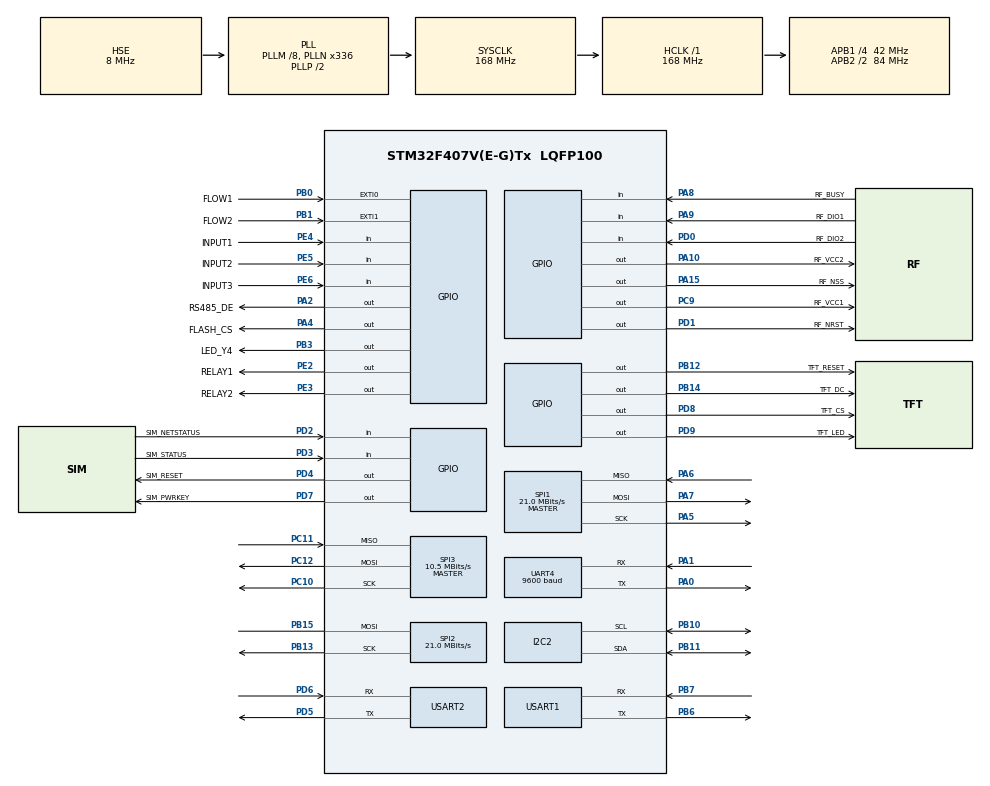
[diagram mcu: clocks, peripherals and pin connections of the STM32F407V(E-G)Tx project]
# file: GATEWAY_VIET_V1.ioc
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Mcu.Family=STM32F4
Mcu.Name=STM32F407V(E-G)Tx
Mcu.Package=LQFP100
NVIC.EXTI0_IRQn=true\:5\:0\:false\:false\:true\:true\:true\:true
NVIC.EXTI1_IRQn=true\:5\:0\:false\:false\:true\:true\:true\:true
NVIC.PriorityGroup=NVIC_PRIORITYGROUP_4
NVIC.UART4_IRQn=true\:5\:0\:false\:false\:true\:true\:true\:true
NVIC.USART1_IRQn=true\:6\:0\:false\:false\:true\:true\:true\:true
NVIC.USART2_IRQn=true\:5\:0\:false\:false\:true\:true\:true\:true
PA0-WKUP.Mode=Asynchronous
PA0-WKUP.Signal=UART4_TX
PA1.Mode=Asynchronous
PA1.Signal=UART4_RX
PA10.GPIO_Label=RF_VCC2
PA10.Signal=GPIO_Output
PA13.Mode=Serial_Wire
PA13.Signal=SYS_JTMS-SWDIO
PA14.Mode=Serial_Wire
PA14.Signal=SYS_JTCK-SWCLK
PA15.GPIO_Label=RF_NSS
PA15.PinState=GPIO_PIN_SET
PA15.Signal=GPIO_Output
PA2.GPIO_Label=RS485_DE
PA2.Signal=GPIO_Output
PA4.GPIO_Label=FLASH_CS
PA4.PinState=GPIO_PIN_SET
PA4.Signal=GPIO_Output
PA5.Mode=Full_Duplex_Master
PA5.Signal=SPI1_SCK
PA6.Mode=Full_Duplex_Master
PA6.Signal=SPI1_MISO
PA7.Mode=Full_Duplex_Master
PA7.Signal=SPI1_MOSI
PA8.GPIO_Label=RF_BUSY
PA8.Signal=GPIO_Input
PA9.GPIO_Label=RF_DIO1
PA9.Signal=GPIO_Input
PB0.GPIO_Label=FLOW1
PB0.GPIO_ModeDefaultEXTI=GPIO_MODE_IT_FALLING
PB0.Signal=GPXTI0
PB1.GPIO_Label=FLOW2
PB1.GPIO_ModeDefaultEXTI=GPIO_MODE_IT_FALLING
PB1.Signal=GPXTI1
PB10.Mode=I2C
PB10.Signal=I2C2_SCL
PB11.Mode=I2C
PB11.Signal=I2C2_SDA
PB12.GPIO_Label=TFT_RESET
PB12.PinState=GPIO_PIN_SET
PB12.Signal=GPIO_Output
PB13.Mode=Simplex_Bidirectional_Master
PB13.Signal=SPI2_SCK
PB14.GPIO_Label=TFT_DC
PB14.Signal=GPIO_Output
PB15.Mode=Simplex_Bidirectional_Master
PB15.Signal=SPI2_MOSI
PB3.GPIO_Label=LED_Y4
PB3.PinState=GPIO_PIN_SET
PB3.Signal=GPIO_Output
PB6.Mode=Asynchronous
PB6.Signal=USART1_TX
PB7.Mode=Asynchronous
PB7.Signal=USART1_RX
PC10.Mode=Full_Duplex_Master
PC10.Signal=SPI3_SCK
PC11.Mode=Full_Duplex_Master
PC11.Signal=SPI3_MISO
PC12.Mode=Full_Duplex_Master
PC12.Signal=SPI3_MOSI
PC14-OSC32_IN.Mode=LSE-External-Oscillator
PC14-OSC32_IN.Signal=RCC_OSC32_IN
PC15-OSC32_OUT.Mode=LSE-External-Oscillator
PC15-OSC32_OUT.Signal=RCC_OSC32_OUT
PC9.GPIO_Label=RF_VCC1
PC9.Signal=GPIO_Output
PD0.GPIO_Label=RF_DIO2
PD0.Signal=GPIO_Input
PD1.GPIO_Label=RF_NRST
PD1.PinState=GPIO_PIN_SET
PD1.Signal=GPIO_Output
PD2.GPIO_Label=SIM_NETSTATUS
PD2.Signal=GPIO_Input
PD3.GPIO_Label=SIM_STATUS
PD3.Signal=GPIO_Input
PD4.GPIO_Label=SIM_RESET
PD4.Signal=GPIO_Output
PD5.Mode=Asynchronous
PD5.Signal=USART2_TX
PD6.Mode=Asynchronous
PD6.Signal=USART2_RX
PD7.GPIO_Label=SIM_PWRKEY
PD7.Signal=GPIO_Output
PD8.GPIO_Label=TFT_CS
PD8.PinState=GPIO_PIN_SET
PD8.Signal=GPIO_Output
PD9.GPIO_Label=TFT_LED
PD9.Signal=GPIO_Output
PE2.GPIO_Label=RELAY1
PE2.Signal=GPIO_Output
PE3.GPIO_Label=RELAY2
PE3.Signal=GPIO_Output
PE4.GPIO_Label=INPUT1
PE4.Signal=GPIO_Input
PE5.GPIO_Label=INPUT2
PE5.Signal=GPIO_Input
PE6.GPIO_Label=INPUT3
PE6.Signal=GPIO_Input
PH0-OSC_IN.Mode=HSE-External-Oscillator
PH0-OSC_IN.Signal=RCC_OSC_IN
PH1-OSC_OUT.Mode=HSE-External-Oscillator
PH1-OSC_OUT.Signal=RCC_OSC_OUT
ProjectManager.HeapSize=0x1000
ProjectManager.StackSize=0x1000
ProjectManager.TargetToolchain=CMake
RCC.AHBFreq_Value=168000000
RCC.APB1CLKDivider=RCC_HCLK_DIV4
RCC.APB1Freq_Value=42000000
RCC.APB1TimFreq_Value=84000000
RCC.APB2CLKDivider=RCC_HCLK_DIV2
RCC.APB2Freq_Value=84000000
RCC.APB2TimFreq_Value=168000000
RCC.CortexFreq_Value=168000000
RCC.HCLKFreq_Value=168000000
RCC.HSE_VALUE=8000000
RCC.HSI_VALUE=16000000
RCC.LSE_VALUE=32768
RCC.PLLM=8
RCC.PLLN=336
RCC.PLLQ=7
RCC.PLLSourceVirtual=RCC_PLLSOURCE_HSE
RCC.RTCClockSelection=RCC_RTCCLKSOURCE_LSE
RCC.SYSCLKFreq_VALUE=168000000
RCC.SYSCLKSource=RCC_SYSCLKSOURCE_PLLCLK
RCC.VCOOutputFreq_Value=336000000
RTC.Format=RTC_FORMAT_BIN
SPI1.BaudRatePrescaler=SPI_BAUDRATEPRESCALER_4
SPI1.CalculateBaudRate=21.0 MBits/s
SPI1.Direction=SPI_DIRECTION_2LINES
SPI1.Mode=SPI_MODE_MASTER
SPI1.VirtualType=VM_MASTER
SPI2.BaudRatePrescaler=SPI_BAUDRATEPRESCALER_2
SPI2.CalculateBaudRate=21.0 MBits/s
SPI2.Direction=SPI_DIRECTION_1LINE
SPI2.Mode=SPI_MODE_MASTER
SPI2.VirtualType=VM_MASTER
SPI3.BaudRatePrescaler=SPI_BAUDRATEPRESCALER_4
SPI3.CalculateBaudRate=10.5 MBits/s
SPI3.Direction=SPI_DIRECTION_2LINES
SPI3.Mode=SPI_MODE_MASTER
SPI3.VirtualType=VM_MASTER
UART4.BaudRate=9600
UART4.VirtualMode=Asynchronous
USART1.VirtualMode=VM_ASYNC
USART2.VirtualMode=VM_ASYNC
VP_RTC_VS_RTC_Activate.Mode=RTC_Enabled
VP_RTC_VS_RTC_Calendar.Mode=RTC_Calendar
board=custom

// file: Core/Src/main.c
/* USER CODE BEGIN Header */
/**
  ******************************************************************************
  * @file           : main.c
  * @brief          : Main program body
  ******************************************************************************
  * @attention
  *
  * Copyright (c) 2026 STMicroelectronics.
  * All rights reserved.
  *
  * This software is licensed under terms that can be found in the LICENSE file
  * in the root directory of this software component.
  * If no LICENSE file comes with this software, it is provided AS-IS.
  *
  ******************************************************************************
  */
/* USER CODE END Header */
#include "main.h"

/* USER CODE BEGIN Includes */
#include "app.h"
/* USER CODE END Includes */

/* USER CODE BEGIN PD */
#define RTC_BKP_MAGIC 0x32F2u   /* trong RTC_BKP_DR1: RTC da duoc khoi tao */
/* USER CODE END PD */

I2C_HandleTypeDef hi2c2;

RTC_HandleTypeDef hrtc;

SPI_HandleTypeDef hspi1;
SPI_HandleTypeDef hspi2;
SPI_HandleTypeDef hspi3;

UART_HandleTypeDef huart4;
UART_HandleTypeDef huart1;
UART_HandleTypeDef huart2;

void SystemClock_Config(void);
static void MX_GPIO_Init(void);
static void MX_USART1_UART_Init(void);
static void MX_USART2_UART_Init(void);
static void MX_I2C2_Init(void);
static void MX_SPI1_Init(void);
static void MX_SPI3_Init(void);
static void MX_UART4_Init(void);
static void MX_SPI2_Init(void);
static void MX_RTC_Init(void);

int main(void)
{

  /* MCU Configuration--------------------------------------------------------*/

  /* Reset of all peripherals, Initializes the Flash interface and the Systick. */
  HAL_Init();

  /* Configure the system clock */
  SystemClock_Config();

  /* Initialize all configured peripherals */
  MX_GPIO_Init();
  MX_USART1_UART_Init();
  MX_USART2_UART_Init();
  MX_I2C2_Init();
  MX_SPI1_Init();
  MX_SPI3_Init();
  MX_UART4_Init();
  MX_SPI2_Init();
  MX_RTC_Init();
  /* USER CODE BEGIN 2 */
  app_init();
  /* USER CODE END 2 */

  /* Infinite loop */
  while (1)
  {

    /* USER CODE BEGIN 3 */
    app_loop();
  }
  /* USER CODE END 3 */
}

void SystemClock_Config(void)
{
  RCC_OscInitTypeDef RCC_OscInitStruct = {0};
  RCC_ClkInitTypeDef RCC_ClkInitStruct = {0};

  /** Configure the main internal regulator output voltage
  */
  __HAL_RCC_PWR_CLK_ENABLE();
  __HAL_PWR_VOLTAGESCALING_CONFIG(PWR_REGULATOR_VOLTAGE_SCALE1);

  /** Initializes the RCC Oscillators according to the specified parameters
  * in the RCC_OscInitTypeDef structure.
  */
  RCC_OscInitStruct.OscillatorType = RCC_OSCILLATORTYPE_HSE|RCC_OSCILLATORTYPE_LSE;
  RCC_OscInitStruct.HSEState = RCC_HSE_ON;
  RCC_OscInitStruct.LSEState = RCC_LSE_ON;
  RCC_OscInitStruct.PLL.PLLState = RCC_PLL_ON;
  RCC_OscInitStruct.PLL.PLLSource = RCC_PLLSOURCE_HSE;
  RCC_OscInitStruct.PLL.PLLM = 8;
  RCC_OscInitStruct.PLL.PLLN = 336;
  RCC_OscInitStruct.PLL.PLLP = RCC_PLLP_DIV2;
  RCC_OscInitStruct.PLL.PLLQ = 7;
  if (HAL_RCC_OscConfig(&RCC_OscInitStruct) != HAL_OK)
  {
    Error_Handler();
  }

  /** Initializes the CPU, AHB and APB buses clocks
  */
  RCC_ClkInitStruct.ClockType = RCC_CLOCKTYPE_HCLK|RCC_CLOCKTYPE_SYSCLK
                              |RCC_CLOCKTYPE_PCLK1|RCC_CLOCKTYPE_PCLK2;
  RCC_ClkInitStruct.SYSCLKSource = RCC_SYSCLKSOURCE_PLLCLK;
  RCC_ClkInitStruct.AHBCLKDivider = RCC_SYSCLK_DIV1;
  RCC_ClkInitStruct.APB1CLKDivider = RCC_HCLK_DIV4;
  RCC_ClkInitStruct.APB2CLKDivider = RCC_HCLK_DIV2;

  if (HAL_RCC_ClockConfig(&RCC_ClkInitStruct, FLASH_LATENCY_5) != HAL_OK)
  {
    Error_Handler();
  }
}

static void MX_I2C2_Init(void)
{

  hi2c2.Instance = I2C2;
  hi2c2.Init.ClockSpeed = 100000;
  hi2c2.Init.DutyCycle = I2C_DUTYCYCLE_2;
  hi2c2.Init.OwnAddress1 = 0;
  hi2c2.Init.AddressingMode = I2C_ADDRESSINGMODE_7BIT;
  hi2c2.Init.DualAddressMode = I2C_DUALADDRESS_DISABLE;
  hi2c2.Init.OwnAddress2 = 0;
  hi2c2.Init.GeneralCallMode = I2C_GENERALCALL_DISABLE;
  hi2c2.Init.NoStretchMode = I2C_NOSTRETCH_DISABLE;
  if (HAL_I2C_Init(&hi2c2) != HAL_OK)
  {
    Error_Handler();
  }

}

static void MX_RTC_Init(void)
{

  RTC_TimeTypeDef sTime = {0};
  RTC_DateTypeDef sDate = {0};

  /** Initialize RTC Only
  */
  hrtc.Instance = RTC;
  hrtc.Init.HourFormat = RTC_HOURFORMAT_24;
  hrtc.Init.AsynchPrediv = 127;
  hrtc.Init.SynchPrediv = 255;
  hrtc.Init.OutPut = RTC_OUTPUT_DISABLE;
  hrtc.Init.OutPutPolarity = RTC_OUTPUT_POLARITY_HIGH;
  hrtc.Init.OutPutType = RTC_OUTPUT_TYPE_OPENDRAIN;
  if (HAL_RTC_Init(&hrtc) != HAL_OK)
  {
    Error_Handler();
  }

  /* USER CODE BEGIN Check_RTC_BKUP */
  /* RTC da chay tu truoc (nguon VBAT giu): khong dat lai ngay gio */
  if (HAL_RTCEx_BKUPRead(&hrtc, RTC_BKP_DR1) == RTC_BKP_MAGIC)
  {
    return;
  }
  /* USER CODE END Check_RTC_BKUP */

  /** Initialize RTC and set the Time and Date
  */
  sTime.Hours = 0;
  sTime.Minutes = 0;
  sTime.Seconds = 0;
  sTime.DayLightSaving = RTC_DAYLIGHTSAVING_NONE;
  sTime.StoreOperation = RTC_STOREOPERATION_RESET;
  if (HAL_RTC_SetTime(&hrtc, &sTime, RTC_FORMAT_BIN) != HAL_OK)
  {
    Error_Handler();
  }
  sDate.WeekDay = RTC_WEEKDAY_MONDAY;
  sDate.Month = RTC_MONTH_JANUARY;
  sDate.Date = 1;
  sDate.Year = 0;

  if (HAL_RTC_SetDate(&hrtc, &sDate, RTC_FORMAT_BIN) != HAL_OK)
  {
    Error_Handler();
  }
  /* USER CODE BEGIN RTC_Init 2 */
  HAL_RTCEx_BKUPWrite(&hrtc, RTC_BKP_DR1, RTC_BKP_MAGIC);
  /* USER CODE END RTC_Init 2 */

}

static void MX_SPI1_Init(void)
{

  /* SPI1 parameter configuration*/
  hspi1.Instance = SPI1;
  hspi1.Init.Mode = SPI_MODE_MASTER;
  hspi1.Init.Direction = SPI_DIRECTION_2LINES;
  hspi1.Init.DataSize = SPI_DATASIZE_8BIT;
  hspi1.Init.CLKPolarity = SPI_POLARITY_LOW;
  hspi1.Init.CLKPhase = SPI_PHASE_1EDGE;
  hspi1.Init.NSS = SPI_NSS_SOFT;
  hspi1.Init.BaudRatePrescaler = SPI_BAUDRATEPRESCALER_4;
  hspi1.Init.FirstBit = SPI_FIRSTBIT_MSB;
  hspi1.Init.TIMode = SPI_TIMODE_DISABLE;
  hspi1.Init.CRCCalculation = SPI_CRCCALCULATION_DISABLE;
  hspi1.Init.CRCPolynomial = 10;
  if (HAL_SPI_Init(&hspi1) != HAL_OK)
  {
    Error_Handler();
  }

}

static void MX_SPI2_Init(void)
{

  /* SPI2 parameter configuration*/
  hspi2.Instance = SPI2;
  hspi2.Init.Mode = SPI_MODE_MASTER;
  hspi2.Init.Direction = SPI_DIRECTION_1LINE;
  hspi2.Init.DataSize = SPI_DATASIZE_8BIT;
  hspi2.Init.CLKPolarity = SPI_POLARITY_LOW;
  hspi2.Init.CLKPhase = SPI_PHASE_1EDGE;
  hspi2.Init.NSS = SPI_NSS_SOFT;
  hspi2.Init.BaudRatePrescaler = SPI_BAUDRATEPRESCALER_2;
  hspi2.Init.FirstBit = SPI_FIRSTBIT_MSB;
  hspi2.Init.TIMode = SPI_TIMODE_DISABLE;
  hspi2.Init.CRCCalculation = SPI_CRCCALCULATION_DISABLE;
  hspi2.Init.CRCPolynomial = 10;
  if (HAL_SPI_Init(&hspi2) != HAL_OK)
  {
    Error_Handler();
  }

}

static void MX_SPI3_Init(void)
{

  /* SPI3 parameter configuration*/
  hspi3.Instance = SPI3;
  hspi3.Init.Mode = SPI_MODE_MASTER;
  hspi3.Init.Direction = SPI_DIRECTION_2LINES;
  hspi3.Init.DataSize = SPI_DATASIZE_8BIT;
  hspi3.Init.CLKPolarity = SPI_POLARITY_LOW;
  hspi3.Init.CLKPhase = SPI_PHASE_1EDGE;
  hspi3.Init.NSS = SPI_NSS_SOFT;
  hspi3.Init.BaudRatePrescaler = SPI_BAUDRATEPRESCALER_4;
  hspi3.Init.FirstBit = SPI_FIRSTBIT_MSB;
  hspi3.Init.TIMode = SPI_TIMODE_DISABLE;
  hspi3.Init.CRCCalculation = SPI_CRCCALCULATION_DISABLE;
  hspi3.Init.CRCPolynomial = 10;
  if (HAL_SPI_Init(&hspi3) != HAL_OK)
  {
    Error_Handler();
  }

}

static void MX_UART4_Init(void)
{

  huart4.Instance = UART4;
  huart4.Init.BaudRate = 9600;
  huart4.Init.WordLength = UART_WORDLENGTH_8B;
  huart4.Init.StopBits = UART_STOPBITS_1;
  huart4.Init.Parity = UART_PARITY_NONE;
  huart4.Init.Mode = UART_MODE_TX_RX;
  huart4.Init.HwFlowCtl = UART_HWCONTROL_NONE;
  huart4.Init.OverSampling = UART_OVERSAMPLING_16;
  if (HAL_UART_Init(&huart4) != HAL_OK)
  {
    Error_Handler();
  }

}

static void MX_USART1_UART_Init(void)
{

  huart1.Instance = USART1;
  huart1.Init.BaudRate = 115200;
  huart1.Init.WordLength = UART_WORDLENGTH_8B;
  huart1.Init.StopBits = UART_STOPBITS_1;
  huart1.Init.Parity = UART_PARITY_NONE;
  huart1.Init.Mode = UART_MODE_TX_RX;
  huart1.Init.HwFlowCtl = UART_HWCONTROL_NONE;
  huart1.Init.OverSampling = UART_OVERSAMPLING_16;
  if (HAL_UART_Init(&huart1) != HAL_OK)
  {
    Error_Handler();
  }

}

static void MX_USART2_UART_Init(void)
{

  huart2.Instance = USART2;
  huart2.Init.BaudRate = 115200;
  huart2.Init.WordLength = UART_WORDLENGTH_8B;
  huart2.Init.StopBits = UART_STOPBITS_1;
  huart2.Init.Parity = UART_PARITY_NONE;
  huart2.Init.Mode = UART_MODE_TX_RX;
  huart2.Init.HwFlowCtl = UART_HWCONTROL_NONE;
  huart2.Init.OverSampling = UART_OVERSAMPLING_16;
  if (HAL_UART_Init(&huart2) != HAL_OK)
  {
    Error_Handler();
  }

}

static void MX_GPIO_Init(void)
{
  GPIO_InitTypeDef GPIO_InitStruct = {0};

  /* GPIO Ports Clock Enable */
  __HAL_RCC_GPIOE_CLK_ENABLE();
  __HAL_RCC_GPIOC_CLK_ENABLE();
  __HAL_RCC_GPIOH_CLK_ENABLE();
  __HAL_RCC_GPIOA_CLK_ENABLE();
  __HAL_RCC_GPIOB_CLK_ENABLE();
  __HAL_RCC_GPIOD_CLK_ENABLE();

  /*Configure GPIO pin Output Level */
  HAL_GPIO_WritePin(GPIOE, RELAY1_Pin|RELAY2_Pin, GPIO_PIN_RESET);

  /*Configure GPIO pin Output Level */
  HAL_GPIO_WritePin(GPIOA, RS485_DE_Pin|RF_VCC2_Pin, GPIO_PIN_RESET);

  /*Configure GPIO pin Output Level */
  HAL_GPIO_WritePin(GPIOA, FLASH_CS_Pin|RF_NSS_Pin, GPIO_PIN_SET);

  /*Configure GPIO pin Output Level */
  HAL_GPIO_WritePin(GPIOB, TFT_RESET_Pin|LED_Y4_Pin, GPIO_PIN_SET);

  /*Configure GPIO pin Output Level */
  HAL_GPIO_WritePin(TFT_DC_GPIO_Port, TFT_DC_Pin, GPIO_PIN_RESET);

  /*Configure GPIO pin Output Level */
  HAL_GPIO_WritePin(GPIOD, TFT_CS_Pin|RF_NRST_Pin, GPIO_PIN_SET);

  /*Configure GPIO pin Output Level */
  HAL_GPIO_WritePin(GPIOD, TFT_LED_Pin|SIM_RESET_Pin|SIM_PWRKEY_Pin, GPIO_PIN_RESET);

  /*Configure GPIO pin Output Level */
  HAL_GPIO_WritePin(RF_VCC1_GPIO_Port, RF_VCC1_Pin, GPIO_PIN_RESET);

  /*Configure GPIO pins : RELAY1_Pin RELAY2_Pin */
  GPIO_InitStruct.Pin = RELAY1_Pin|RELAY2_Pin;
  GPIO_InitStruct.Mode = GPIO_MODE_OUTPUT_PP;
  GPIO_InitStruct.Pull = GPIO_NOPULL;
  GPIO_InitStruct.Speed = GPIO_SPEED_FREQ_LOW;
  HAL_GPIO_Init(GPIOE, &GPIO_InitStruct);

  /*Configure GPIO pins : INPUT1_Pin INPUT2_Pin INPUT3_Pin */
  GPIO_InitStruct.Pin = INPUT1_Pin|INPUT2_Pin|INPUT3_Pin;
  GPIO_InitStruct.Mode = GPIO_MODE_INPUT;
  GPIO_InitStruct.Pull = GPIO_NOPULL;
  HAL_GPIO_Init(GPIOE, &GPIO_InitStruct);

  /*Configure GPIO pins : RS485_DE_Pin FLASH_CS_Pin RF_VCC2_Pin RF_NSS_Pin */
  GPIO_InitStruct.Pin = RS485_DE_Pin|FLASH_CS_Pin|RF_VCC2_Pin|RF_NSS_Pin;
  GPIO_InitStruct.Mode = GPIO_MODE_OUTPUT_PP;
  GPIO_InitStruct.Pull = GPIO_NOPULL;
  GPIO_InitStruct.Speed = GPIO_SPEED_FREQ_LOW;
  HAL_GPIO_Init(GPIOA, &GPIO_InitStruct);

  /*Configure GPIO pins : FLOW1_Pin FLOW2_Pin */
  GPIO_InitStruct.Pin = FLOW1_Pin|FLOW2_Pin;
  GPIO_InitStruct.Mode = GPIO_MODE_IT_FALLING;
  GPIO_InitStruct.Pull = GPIO_NOPULL;
  HAL_GPIO_Init(GPIOB, &GPIO_InitStruct);

  /*Configure GPIO pins : TFT_RESET_Pin TFT_DC_Pin LED_Y4_Pin */
  GPIO_InitStruct.Pin = TFT_RESET_Pin|TFT_DC_Pin|LED_Y4_Pin;
  GPIO_InitStruct.Mode = GPIO_MODE_OUTPUT_PP;
  GPIO_InitStruct.Pull = GPIO_NOPULL;
  GPIO_InitStruct.Speed = GPIO_SPEED_FREQ_LOW;
  HAL_GPIO_Init(GPIOB, &GPIO_InitStruct);

  /*Configure GPIO pins : TFT_CS_Pin TFT_LED_Pin RF_NRST_Pin SIM_RESET_Pin
                           SIM_PWRKEY_Pin */
  GPIO_InitStruct.Pin = TFT_CS_Pin|TFT_LED_Pin|RF_NRST_Pin|SIM_RESET_Pin
                          |SIM_PWRKEY_Pin;
  GPIO_InitStruct.Mode = GPIO_MODE_OUTPUT_PP;
  GPIO_InitStruct.Pull = GPIO_NOPULL;
  GPIO_InitStruct.Speed = GPIO_SPEED_FREQ_LOW;
  HAL_GPIO_Init(GPIOD, &GPIO_InitStruct);

  /*Configure GPIO pin : RF_VCC1_Pin */
  GPIO_InitStruct.Pin = RF_VCC1_Pin;
  GPIO_InitStruct.Mode = GPIO_MODE_OUTPUT_PP;
  GPIO_InitStruct.Pull = GPIO_NOPULL;
  GPIO_InitStruct.Speed = GPIO_SPEED_FREQ_LOW;
  HAL_GPIO_Init(RF_VCC1_GPIO_Port, &GPIO_InitStruct);

  /*Configure GPIO pins : RF_BUSY_Pin RF_DIO1_Pin */
  GPIO_InitStruct.Pin = RF_BUSY_Pin|RF_DIO1_Pin;
  GPIO_InitStruct.Mode = GPIO_MODE_INPUT;
  GPIO_InitStruct.Pull = GPIO_NOPULL;
  HAL_GPIO_Init(GPIOA, &GPIO_InitStruct);

  /*Configure GPIO pins : RF_DIO2_Pin SIM_NETSTATUS_Pin SIM_STATUS_Pin */
  GPIO_InitStruct.Pin = RF_DIO2_Pin|SIM_NETSTATUS_Pin|SIM_STATUS_Pin;
  GPIO_InitStruct.Mode = GPIO_MODE_INPUT;
  GPIO_InitStruct.Pull = GPIO_NOPULL;
  HAL_GPIO_Init(GPIOD, &GPIO_InitStruct);

  /* EXTI interrupt init*/
  HAL_NVIC_SetPriority(EXTI0_IRQn, 5, 0);
  HAL_NVIC_EnableIRQ(EXTI0_IRQn);

  HAL_NVIC_SetPriority(EXTI1_IRQn, 5, 0);
  HAL_NVIC_EnableIRQ(EXTI1_IRQn);

}

void Error_Handler(void)
{
  __disable_irq();
  while (1)
  {
  }
}
